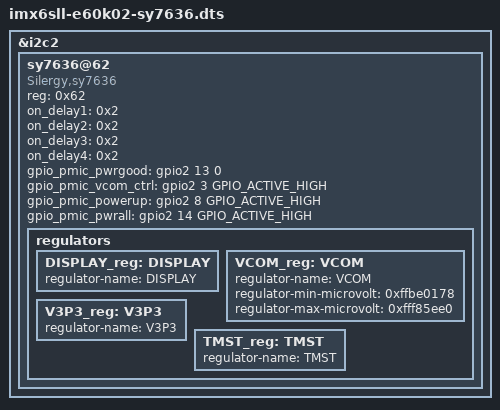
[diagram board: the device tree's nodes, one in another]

#include "imx6sll-e60k02-base.dts"

&i2c2 {
	sy7636@62 {
		compatible = "Silergy,sy7636";
		reg = <0x62>;
		/*
		 * power on delay for SY7636
		 * 0x0 : 0ms
		 * 0x1 : 1ms
		 * 0x2 : 2ms
		 * 0x3 : 4ms
		 * chip default is 2ms .
		 */
		on_delay1 = <0x2>;
		on_delay2 = <0x2>;
		on_delay3 = <0x2>;
		on_delay4 = <0x2>;


		/*
		 * VLDO Voltage Adjustment Control 
		 * 0x0 = reserved
		 * 0x1 = +/-18V
		 * 0x2 = +/-15.25V
		 * 0x3 = +/-15V (default)
		 * 0x4 = +/-14.75V
		 * 0x5 = +/-14.5V
		 * 0x6 = +/-14.25V
		 * 0x7 = reserved
		VLDO = <0x2>;
		 */
		
		gpio_pmic_pwrgood = <&gpio2 13 0>;
		gpio_pmic_vcom_ctrl = <&gpio2 3 GPIO_ACTIVE_HIGH>;
		gpio_pmic_powerup = <&gpio2 8 GPIO_ACTIVE_HIGH>;

		/* gpio_pmic_v3p3 = <&gpio2 14 GPIO_ACTIVE_HIGH>; */
		gpio_pmic_pwrall = <&gpio2 14 GPIO_ACTIVE_HIGH>;

		regulators {
			DISPLAY_reg: DISPLAY {
				regulator-name = "DISPLAY";
			};

			VCOM_reg: VCOM {
				regulator-name = "VCOM";
				/* 2's-compliment, -4325000 */
				regulator-min-microvolt = <0xffbe0178>;
				/* 2's-compliment, -500000 */
				regulator-max-microvolt = <0xfff85ee0>;
			};

			V3P3_reg: V3P3 {
				regulator-name = "V3P3";
			};

			TMST_reg: TMST {
				regulator-name = "TMST";
			};

		};
	};
};


